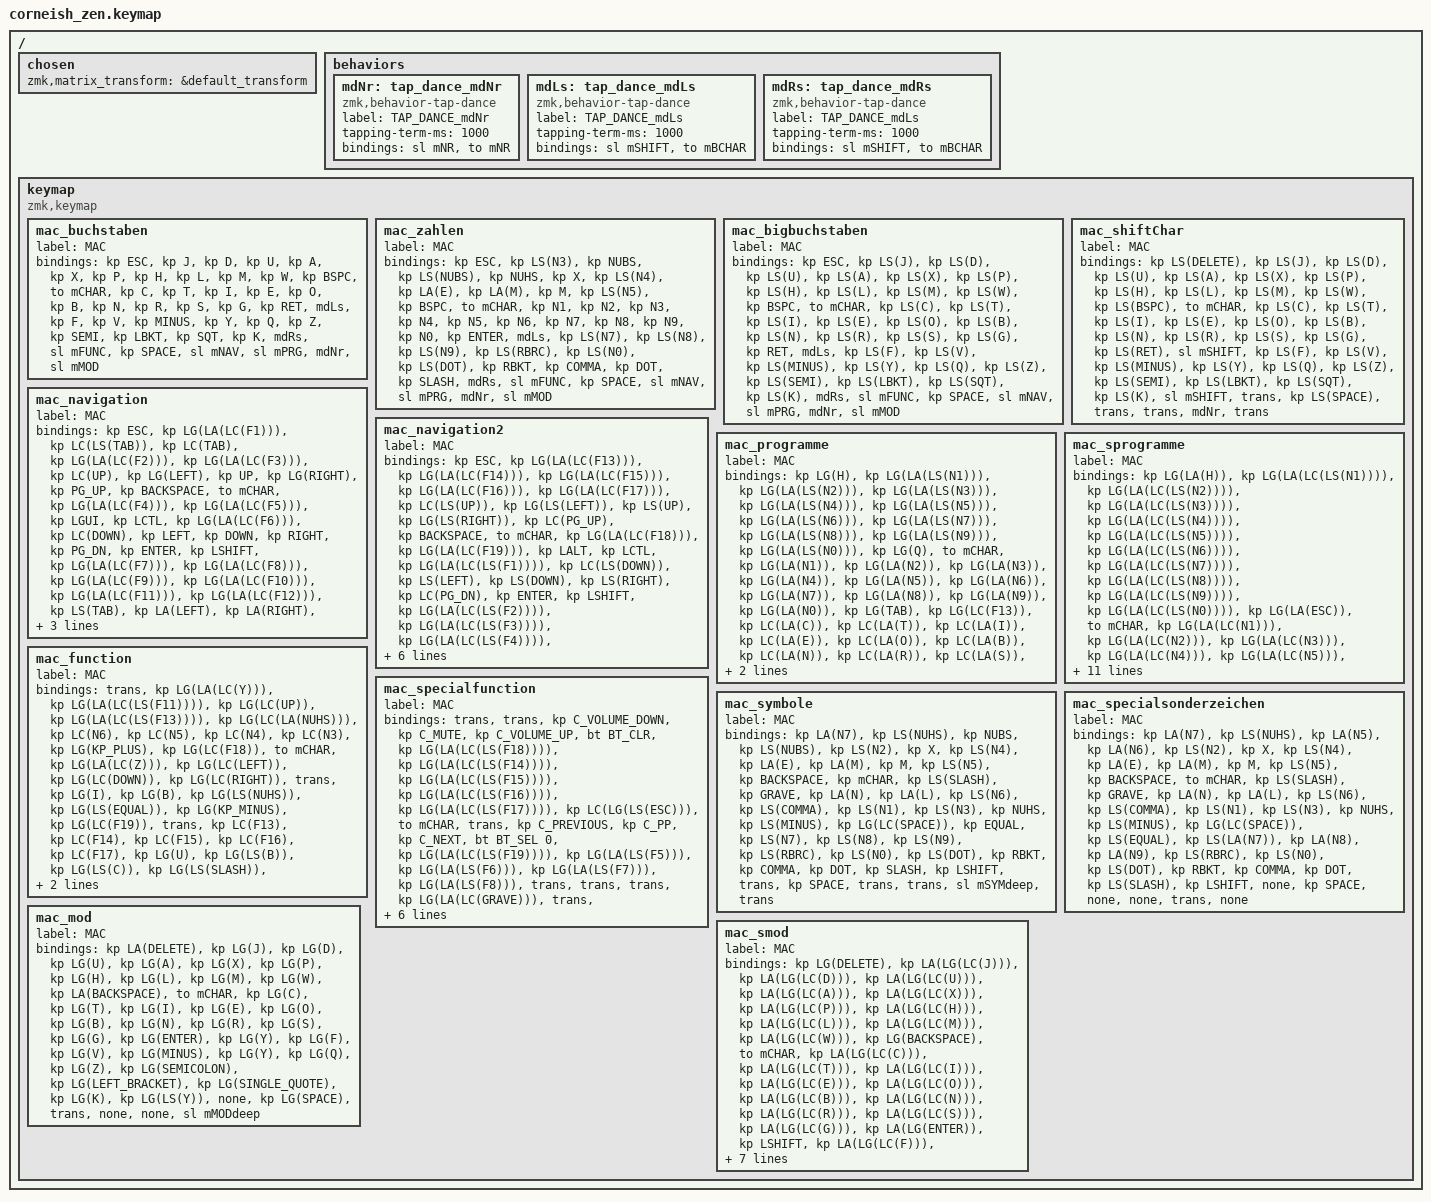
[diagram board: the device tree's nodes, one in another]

#include <behaviors.dtsi>
#include <dt-bindings/zmk/keys.h>
#include <dt-bindings/zmk/bt.h>


#define mCHAR 0
#define mNR 1

#define mBCHAR 2
#define mSHIFT 3

#define mNAV 4
#define mNAVdeep 5

#define mPRG 6
#define mPRGdeep 7

#define mFUNC 8
#define mFUNCdeep 9

#define mSYM 10
#define mSYMdeep 11

#define mMOD 12
#define mMODdeep 13


/ {
    chosen {
    	zmk,matrix_transform = &default_transform;
    };
};



/ {

    behaviors {
        mdNr: tap_dance_mdNr {
            compatible = "zmk,behavior-tap-dance";
            label = "TAP_DANCE_mdNr";
            #binding-cells = <0>;
            tapping-term-ms = <1000>;
            bindings = <&sl mNR>, <&to mNR>;
        };
		mdLs: tap_dance_mdLs {
            compatible = "zmk,behavior-tap-dance";
            label = "TAP_DANCE_mdLs";
            #binding-cells = <0>;
            tapping-term-ms = <1000>;
            bindings = <&sl mSHIFT>, <&to mBCHAR>;
        };
		mdRs: tap_dance_mdRs {
            compatible = "zmk,behavior-tap-dance";
            label = "TAP_DANCE_mdLs";
            #binding-cells = <0>;
            tapping-term-ms = <1000>;
            bindings = <&sl mSHIFT>, <&to mBCHAR>;
        };
    };
	

	keymap
	{	
		compatible = "zmk,keymap";

		// --------------------------------------
		// Layer 0 - mChar = 	  Buchstaben	
		// --------------------------------------
	
		mac_buchstaben
		{
			label = "MAC";

			bindings = <

				&kp ESC
				&kp J 
				&kp D	 
				&kp U
				&kp A
				&kp X
				&kp P
				&kp H
				&kp L
				&kp M
				&kp W
				&kp BSPC
	
				&to mCHAR
				&kp C
				&kp T
				&kp I
				&kp E
				&kp O
				&kp B
				&kp N
				&kp R
				&kp S
				&kp G
				&kp RET
	
				&mdLs
				&kp F
				&kp V
				&kp MINUS
				&kp Y
				&kp Q
				&kp Z
				&kp SEMI
				&kp LBKT
				&kp SQT
				&kp K
				&mdRs

				&sl mFUNC
				&kp SPACE
				&sl mNAV
				&sl mPRG
				&mdNr
				&sl mMOD
			>;
		};



		// --------------------------------------
		// Layer 1 - mNR = 	  Zahlen	
		// --------------------------------------

		mac_zahlen
		{
			label = "MAC";

			bindings = <

				&kp ESC	
				&kp LS(N3)
				&kp NUBS
				&kp LS(NUBS)			
				&kp NUHS
				&kp X
				&kp LS(N4)
				&kp LA(E)
				&kp LA(M)
				&kp M
				&kp LS(N5)			
				&kp BSPC

				&to mCHAR
				&kp N1				
				&kp N2				
				&kp N3				
				&kp N4					
				&kp N5				
				&kp N6				
				&kp N7				
				&kp N8				
				&kp N9				
				&kp N0				
				&kp ENTER 

				&mdLs
				&kp LS(N7)
				&kp LS(N8)
				&kp LS(N9)
				&kp LS(RBRC)
				&kp LS(N0)
				&kp LS(DOT)
				&kp RBKT
				&kp COMMA
				&kp DOT
				&kp SLASH		
				&mdRs
		
				&sl mFUNC
				&kp SPACE 
				&sl mNAV
				&sl mPRG
				&mdNr
				&sl mMOD
			>;		
		};



		// --------------------------------------
		// Layer 2 - mBCHAR = 	 Großbuchstaben	
		// --------------------------------------
	
		mac_bigbuchstaben
		{
			label = "MAC";

			bindings = <

				&kp ESC
				&kp LS(J) 
				&kp LS(D)	 
				&kp LS(U)
				&kp LS(A)
				&kp LS(X)
				&kp LS(P)
				&kp LS(H)
				&kp LS(L)
				&kp LS(M)
				&kp LS(W)
				&kp BSPC
	
				&to mCHAR
				&kp LS(C)
				&kp LS(T)
				&kp LS(I)
				&kp LS(E)
				&kp LS(O)
				&kp LS(B)
				&kp LS(N)
				&kp LS(R)
				&kp LS(S)
				&kp LS(G)
				&kp RET
	
				&mdLs
				&kp LS(F)
				&kp LS(V)
				&kp LS(MINUS)
				&kp LS(Y)
				&kp LS(Q)
				&kp LS(Z)
				&kp LS(SEMI)
				&kp LS(LBKT)
				&kp LS(SQT)
				&kp LS(K)
				&mdRs

				&sl mFUNC
				&kp SPACE 
				&sl mNAV
				&sl mPRG
				&mdNr
				&sl mMOD
			>;
		};



		// --------------------------------------
		// Layer 3 - mSHIFT = 	  Shift Buchstaben	
		// --------------------------------------
	
		mac_shiftChar
		{
			label = "MAC";

			bindings = <

				&kp LS(DELETE)
				&kp LS(J) 
				&kp LS(D)	 
				&kp LS(U)
				&kp LS(A)
				&kp LS(X)
				&kp LS(P)
				&kp LS(H)
				&kp LS(L)
				&kp LS(M)
				&kp LS(W)
				&kp LS(BSPC)
	
				&to mCHAR
				&kp LS(C)
				&kp LS(T)
				&kp LS(I)
				&kp LS(E)
				&kp LS(O)
				&kp LS(B)
				&kp LS(N)
				&kp LS(R)
				&kp LS(S)
				&kp LS(G)
				&kp LS(RET)
	
				&sl mSHIFT
				&kp LS(F)
				&kp LS(V)
				&kp LS(MINUS)
				&kp LS(Y)
				&kp LS(Q)
				&kp LS(Z)
				&kp LS(SEMI)
				&kp LS(LBKT)
				&kp LS(SQT)
				&kp LS(K)
				&sl mSHIFT

				&trans
				&kp LS(SPACE)
				&trans
				&trans
				&mdNr
				&trans
			>;
		};


		// --------------------------------------
		// Layer = 4 - mNAV - Navigation
		// -------------------------------------

		mac_navigation
		{		
			label = "MAC";

			bindings = <

				&kp ESC
				&kp LG(LA(LC(F1)))		  	// open
				&kp LC(LS(TAB))				// Tap Switch
				&kp LC(TAB)		  			// Tab Switch 
				&kp LG(LA(LC(F2)))		  	// open
				&kp LG(LA(LC(F3)))		  	// Clipboard History
				&kp LC(UP)					// Home Sprung
				&kp LG(LEFT) 				// Home 
				&kp UP						// Up
				&kp LG(RIGHT) 				// END 
				&kp PG_UP 					// Page Up
				&kp BACKSPACE				// Backspace

				&to mCHAR
				&kp LG(LA(LC(F4)))		  	// Pfadsuche
				&kp LG(LA(LC(F5)))		  	// Umbennen
				&kp LGUI					// App Switch
				&kp LCTL					// Craft
				&kp LG(LA(LC(F6)))		  	// Fokus
				&kp LC(DOWN) 				// End Sprung
				&kp LEFT 					// Left
				&kp DOWN					// Down
				&kp RIGHT 					// Right
				&kp PG_DN					// Page Down
				&kp ENTER					// Enter
				
				&kp LSHIFT					// Shift
				&kp LG(LA(LC(F7)))		  	// Seitenleiste links
				&kp LG(LA(LC(F8)))		  	// Pfad zurück
				&kp LG(LA(LC(F9)))		  	// Pfad vor
				&kp LG(LA(LC(F10)))		  	// Seitenleiste rechts
				&kp LG(LA(LC(F11)))		  	// open
				&kp LG(LA(LC(F12)))		  	// open
				&kp LS(TAB)					// zurück
				&kp LA(LEFT)				// Wort Sprung
				&kp LA(RIGHT)				// Wort Sprung
				&kp TAB						// vor
				&kp DEL 					// Delete

				&none
				&kp LG(LA(LC(LS(MINUS))))	// Shortcat
				&sl mNAVdeep				// deep
				&trans
				&trans
				&trans						
			>;
		};



		// --------------------------------------
		// Layer = 5 - mNAVdeep - deep Navigation
		// -------------------------------------

		mac_navigation2
		{		
			label = "MAC";

			bindings = <

				&kp ESC
				&kp LG(LA(LC(F13)))		  	// Open
				&kp LG(LA(LC(F14)))		  	// Open
				&kp LG(LA(LC(F15)))		  	// Open
				&kp LG(LA(LC(F16)))		  	// Open
				&kp LG(LA(LC(F17)))		  	// Open
				&kp LC(LS(UP))				// Home Sprung
				&kp LG(LS(LEFT)) 			// Home 
				&kp LS(UP)					// Shift Up
				&kp LG(LS(RIGHT))			// End
				&kp LC(PG_UP) 				// deep page
				&kp BACKSPACE

				&to mCHAR
				&kp LG(LA(LC(F18)))		  	// Open
				&kp LG(LA(LC(F19)))		  	// Open
				&kp LALT					// LALT
				&kp LCTL					// CTL
				&kp LG(LA(LC(LS(F1))))	  	// Outlook
				&kp LC(LS(DOWN)) 			// End Sprung Markierung
				&kp LS(LEFT) 				// Shift Left
				&kp LS(DOWN)				// Shift Down
				&kp LS(RIGHT) 				// Shift Right
				&kp LC(PG_DN)				// Control Page
				&kp ENTER
				
				&kp LSHIFT					// Shift
				&kp LG(LA(LC(LS(F2))))		// Outlook
				&kp LG(LA(LC(LS(F3))))		// Zurück History 
				&kp LG(LA(LC(LS(F4))))		// Vor History
				&kp LG(LA(LC(LS(F5))))		// Outlook
				&kp LG(LA(LC(LS(F6))))		// open			
				&kp LG(LA(LC(LS(F7))))		// open
				&kp LG(LA(LS(TAB)))			// TAB Alt
				&kp LA(LS(LEFT))			// Shift Wort Sprung
				&kp LA(LS(RIGHT))			// Shift Wort Sprung
				&kp LG(LA(TAB))				// TAB Alt
				&kp DEL 					// Delete

				&none
				&trans
				&trans
				&trans
				&trans
				&trans
			>;
		};




		// --------------------------------------
		// Layer 6 - mPRG =	Programme
		// --------------------------------------


		mac_programme
		{
			label = "MAC";

			bindings = <

				&kp LG(H)					// Hide
				&kp LG(LA(LS(N1)))
				&kp LG(LA(LS(N2)))
				&kp LG(LA(LS(N3)))
				&kp LG(LA(LS(N4)))
				&kp LG(LA(LS(N5)))
				&kp LG(LA(LS(N6)))
				&kp LG(LA(LS(N7)))
				&kp LG(LA(LS(N8)))
				&kp LG(LA(LS(N9)))
				&kp LG(LA(LS(N0)))
				&kp LG(Q) 					// Quit

				&to mCHAR		
				&kp LG(LA(N1))
				&kp LG(LA(N2))
				&kp LG(LA(N3))
				&kp LG(LA(N4))
				&kp LG(LA(N5))
				&kp LG(LA(N6))
				&kp LG(LA(N7))
				&kp LG(LA(N8))
				&kp LG(LA(N9))
				&kp LG(LA(N0))
				&kp LG(TAB)

				&kp LG(LC(F13))
				&kp LC(LA(C))
				&kp LC(LA(T))
				&kp LC(LA(I))
				&kp LC(LA(E))
				&kp LC(LA(O))
				&kp LC(LA(B))
				&kp LC(LA(N))
				&kp LC(LA(R))
				&kp LC(LA(S))
				&kp LC(LA(G))
				&kp LG(LC(F14))
		
				&none
				&none
				&kp LG(SPACE)
				&sl mPRGdeep
				&sl mSYM
				&none
			>;
		};


		// --------------------------------------
		// Layer 7 - mPRGdeep =	deep Programme
		// --------------------------------------


		mac_sprogramme
		{

			label = "MAC";

			bindings = <

				&kp LG(LA(H))					// Hard Hide
				&kp LG(LA(LC(LS(N1)))) 			
				&kp LG(LA(LC(LS(N2))))
				&kp LG(LA(LC(LS(N3))))
				&kp LG(LA(LC(LS(N4))))
				&kp LG(LA(LC(LS(N5))))
				&kp LG(LA(LC(LS(N6))))
				&kp LG(LA(LC(LS(N7))))
				&kp LG(LA(LC(LS(N8))))
				&kp LG(LA(LC(LS(N9))))
				&kp LG(LA(LC(LS(N0))))
				&kp LG(LA(ESC))					// Hard Quit
		
				&to mCHAR		
				&kp LG(LA(LC(N1)))
				&kp LG(LA(LC(N2)))
				&kp LG(LA(LC(N3)))
				&kp LG(LA(LC(N4)))
				&kp LG(LA(LC(N5)))
				&kp LG(LA(LC(N6)))
				&kp LG(LA(LC(N7)))
				&kp LG(LA(LC(N8)))
				&kp LG(LA(LC(N9)))
				&kp LG(LA(LC(N0)))
				&kp LG(LC(F15))

				&kp LG(LC(F16))
				&kp LC(LA(LS(C)))
				&kp LC(LA(LS(T)))
				&kp LC(LA(LS(I)))
				&kp LC(LA(LS(E)))
				&kp LC(LA(LS(O)))
				&kp LC(LA(LS(B)))
				&kp LC(LA(LS(N)))
				&kp LC(LA(LS(R)))				
				&kp LC(LA(LS(S)))
				&kp LC(LA(LS(G)))
				&kp LG(LC(F17))
		
				&none
				&none
				&kp LG(LA(LC(SPACE)))	 	 	// Maestro Spotlight
				&trans
				&none
				&none
			>;
		};


		// --------------------------------------
		// Layer 8 - mFUNC =	Funktionen
		// --------------------------------------

		mac_function
		{
			label = "MAC";

			bindings = <
	
				&trans
				&kp LG(LA(LC(Y)))			// drehen
				&kp LG(LA(LC(LS(F11))))		// Window size
				&kp LG(LC(UP))				// Window Move
				&kp LG(LA(LC(LS(F13))))		// Window size
				&kp LG(LC(LA(NUHS)))   		// Screenshot
				&kp LC(N6)					// Craft Format
				&kp LC(N5)					// Craft Format
				&kp LC(N4)					// Craft Format
				&kp LC(N3)					// Craft Format   
				&kp LG(KP_PLUS)				// Plus
				&kp LG(LC(F18))				// free

				&to mCHAR
				&kp LG(LA(LC(Z)))			// drehen	
				&kp LG(LC(LEFT))			// Window Move
				&kp LG(LC(DOWN))			// Window Move
				&kp LG(LC(RIGHT))			// Window Move
				&trans			
				&kp LG(I)					// Craft Format
				&kp LG(B) 					// Craft Format
				&kp LG(LS(NUHS))			// Craft Format (Focus)
				&kp LG(LS(EQUAL))			// Craft Format (Block)
				&kp LG(KP_MINUS) 			// Minus
				&kp LG(LC(F19))				// free

				&trans
				&kp LC(F13)
				&kp LC(F14)
				&kp LC(F15)
				&kp LC(F16)
				&kp LC(F17)
				&kp LG(U) 					// Craft Format
				&kp LG(LS(B))				// Craft Format
				&kp LG(LS(C))				// Craft Format
				&kp LG(LS(SLASH))			// Craft Format (Durch)
				&kp LG(LS(P))				// Craft Format (Seite)
				&kp LG(LC(F20))				// free

				&sl mFUNCdeep
				&none
				&none
				&none
				&none
				&none
			>;
		};


		// --------------------------------------
		// Layer 9 - mFUNCdeep =	deep Funktionen
		// --------------------------------------

		mac_specialfunction
		{
			label = "MAC";

			bindings = <

				&trans
				&trans
				&kp C_VOLUME_DOWN 
				&kp C_MUTE
				&kp C_VOLUME_UP 
				&bt BT_CLR 	
				&kp LG(LA(LC(LS(F18))))		// 
				&kp LG(LA(LC(LS(F14))))		// 
				&kp LG(LA(LC(LS(F15))))		// 
				&kp LG(LA(LC(LS(F16))))		// 
				&kp LG(LA(LC(LS(F17))))		// 
				&kp LC(LG(LS(ESC)))			// Herunterfahren

				&to mCHAR
				&trans
				&kp C_PREVIOUS 
				&kp C_PP
				&kp C_NEXT  
				&bt BT_SEL 0
				&kp LG(LA(LC(LS(F19))))		// 
				&kp LG(LA(LS(F5)))			//
				&kp LG(LA(LS(F6)))			//
				&kp LG(LA(LS(F7)))			//
				&kp LG(LA(LS(F8)))			//
				&trans

				&trans
				&trans
				&kp LG(LA(LC(GRAVE)))		// Bright
				&trans
				&kp LG(LA(LC(EQUAL)))		// Bright
				&bt BT_NXT 
				&trans
				&kp LG(LA(LC(LS(F8))))		// Window size
				&kp LG(LA(LC(LS(F9))))		// Window size
				&kp LG(LA(LC(LS(F10))))		// Window size
				&kp LG(LA(LC(LS(F12))))		// Window size
				&trans
		
				&trans
				&none
				&none
				&none
				&none
				&none
 
			>;
		};

		



		// --------------------------------------
		// Layer 10 - mSYM =	Symoble
		// --------------------------------------

		mac_symbole
		{
			label = "MAC";

			bindings = <
				
				&kp LA(N7)					// |
				&kp LS(NUHS)				// '
				&kp NUBS					// <
				&kp LS(NUBS)				// >
				&kp LS(N2)					// "
				&kp X						// X
				&kp LS(N4)					// $
				&kp LA(E)					// €
				&kp LA(M)					// µ
				&kp M						// m
				&kp LS(N5)					// %
				&kp BACKSPACE			

				&kp mCHAR
				&kp LS(SLASH)				// _
				&kp GRAVE					// ^
				&kp LA(N)					// ~
				&kp LA(L)					// @
				&kp LS(N6)					// &
				&kp LS(COMMA)				// ;
				&kp LS(N1)					// !
				&kp LS(N3)					// §
				&kp NUHS					// #
				&kp LS(MINUS)				// ?
				&kp LG(LC(SPACE))   		// Sonderzeichen

				&kp EQUAL					// ´
				&kp LS(N7)					// /
				&kp LS(N8)					// (
				&kp LS(N9)					// )
				&kp LS(RBRC)				// *
				&kp LS(N0)					// =
				&kp LS(DOT)					// :
				&kp RBKT					// +
				&kp COMMA					// ,
				&kp DOT						// .
				&kp SLASH					// -
				&kp LSHIFT					
		
				&trans 
				&kp SPACE
				&trans
				&trans
				&sl mSYMdeep
				&trans
			>;
		};



		// --------------------------------------
		// Layer 11 - mSYMdeep =	deep Symbole
		// --------------------------------------

		mac_specialsonderzeichen
		{
			label = "MAC";

			bindings = <

				&kp LA(N7)					// |
				&kp LS(NUHS)				// '
				&kp LA(N5)					// [
				&kp LA(N6)					// ]
				&kp LS(N2)					// "
				&kp X						// x
				&kp LS(N4)					// $
				&kp LA(E)					// €
				&kp LA(M)					// µ
				&kp M						// m
				&kp LS(N5)					// %
				&kp BACKSPACE

				&to mCHAR
				&kp LS(SLASH)				// _
				&kp GRAVE					// ^
				&kp LA(N)					// ~
				&kp LA(L)					// @
				&kp LS(N6)					// &
				&kp LS(COMMA)				// ;
				&kp LS(N1)					// !
				&kp LS(N3)					// §
				&kp NUHS					// #
				&kp LS(MINUS)				// ?
				&kp LG(LC(SPACE))   		// Sonderzeichen

				&kp LS(EQUAL)				// `
				&kp LS(LA(N7))				// backsl
				&kp LA(N8)					// {
				&kp LA(N9)					// }
				&kp LS(RBRC)				// *
				&kp LS(N0)					// =
				&kp LS(DOT)					// :
				&kp RBKT					// +
				&kp COMMA					// ,
				&kp DOT						// .
				&kp LS(SLASH)				// _
				&kp LSHIFT				

				&none
				&kp SPACE
				&none
				&none
				&trans
				&none
			>;
		};	





		// --------------------------------------
		// Layer 12 - mMOD =	GUI
		// --------------------------------------

		mac_mod
		{
			label = "MAC";

			bindings = <

				&kp LA(DELETE)				// Wort entfernen
				&kp LG(J)
				&kp LG(D)
				&kp LG(U)
				&kp LG(A)
				&kp LG(X)
				&kp LG(P)
				&kp LG(H)
				&kp LG(L) 
				&kp LG(M)
				&kp LG(W) 
				&kp LA(BACKSPACE)			// Wort enfternen
		
				&to mCHAR
				&kp LG(C)
				&kp LG(T)
				&kp LG(I)
				&kp LG(E)
				&kp LG(O)	
				&kp LG(B)
				&kp LG(N)
				&kp LG(R)
				&kp LG(S)
				&kp LG(G)
				&kp LG(ENTER)				// Enter Mod	

				&kp LG(Y)					// Zurück
				&kp LG(F)
				&kp LG(V)
				&kp LG(MINUS)
				&kp LG(Y)
				&kp LG(Q)
				&kp LG(Z)
				&kp LG(SEMICOLON)
				&kp LG(LEFT_BRACKET)
				&kp LG(SINGLE_QUOTE)
				&kp LG(K) 
				&kp LG(LS(Y))				// Vor
		
				&none
				&kp LG(SPACE)
				&trans
				&none
				&none
				&sl mMODdeep
			>;
		};



		// --------------------------------------
		// Layer 13 - mMODdeep =	deep GUI
		// --------------------------------------

		mac_smod
		{	
			label = "MAC";

			bindings = <
			
				&kp LG(DELETE)				// Zeile entfernen 
				&kp LA(LG(LC(J)))
				&kp LA(LG(LC(D)))
				&kp LA(LG(LC(U)))
				&kp LA(LG(LC(A)))
				&kp LA(LG(LC(X)))
				&kp LA(LG(LC(P)))
				&kp LA(LG(LC(H))) 
				&kp LA(LG(LC(L))) 
				&kp LA(LG(LC(M)))
				&kp LA(LG(LC(W)))
				&kp LG(BACKSPACE)			// Zeile enfternen
		
				&to mCHAR
				&kp LA(LG(LC(C)))
				&kp LA(LG(LC(T)))
				&kp LA(LG(LC(I)))
				&kp LA(LG(LC(E)))
				&kp LA(LG(LC(O)))
				&kp LA(LG(LC(B)))
				&kp LA(LG(LC(N)))
				&kp LA(LG(LC(R)))
				&kp LA(LG(LC(S)))
				&kp LA(LG(LC(G)))
				&kp LA(LG(ENTER))			// Enter Mod

				&kp LSHIFT
				&kp LA(LG(LC(F)))
				&kp LA(LG(LC(V)))
				&kp LA(LG(LC(MINUS)))
				&kp LA(LG(LC(Y)))
				&kp LA(LG(LC(Q)))
				&kp LA(LG(LC(Z)))
				&kp LA(LG(LC(SEMICOLON)))
				&kp LA(LG(LC(LEFT_BRACKET)))
				&kp LA(LG(LC(SINGLE_QUOTE)))
				&kp LA(LG(LC(K)))
				&kp LSHIFT

				&none
				&kp LS(SPACE)
				&trans
				&none
				&none
				&trans
			>;
		};


	};
};
